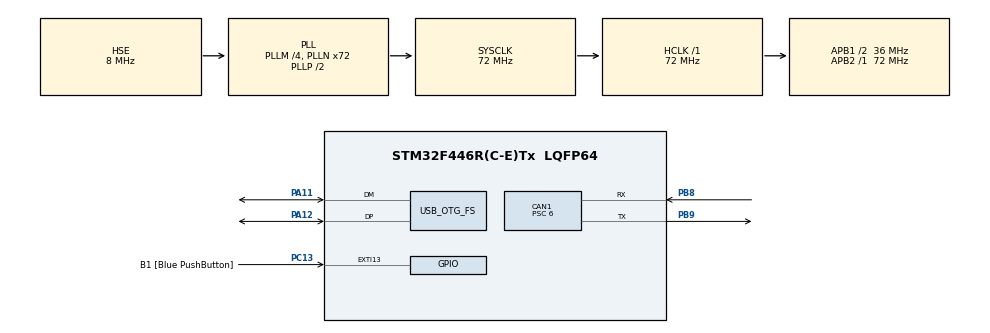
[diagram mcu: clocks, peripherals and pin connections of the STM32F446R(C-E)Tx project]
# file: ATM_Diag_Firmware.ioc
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CAN1.BS1=CAN_BS1_12TQ
CAN1.BS2=CAN_BS2_1TQ
CAN1.CalculateBaudRate=428571
CAN1.CalculateTimeBit=2333
CAN1.CalculateTimeQuantum=166.66666666666669
CAN1.NART=ENABLE
CAN1.Prescaler=6
FREERTOS.Tasks01=defaultTask,24,128,StartDefaultTask,Default,NULL,Dynamic,NULL,NULL
FREERTOS.configENABLE_FPU=1
FREERTOS.configUSE_NEWLIB_REENTRANT=1
Mcu.Family=STM32F4
Mcu.Name=STM32F446R(C-E)Tx
Mcu.Package=LQFP64
NVIC.CAN1_RX0_IRQn=true\:6\:0\:true\:false\:true\:true\:true\:true\:true
NVIC.CAN1_TX_IRQn=true\:7\:0\:true\:false\:true\:true\:true\:true\:true
NVIC.OTG_FS_IRQn=true\:5\:0\:true\:false\:true\:true\:true\:true\:true
NVIC.PriorityGroup=NVIC_PRIORITYGROUP_4
NVIC.TIM2_IRQn=true\:15\:0\:false\:false\:true\:false\:false\:true\:true
NVIC.TimeBase=TIM2_IRQn
NVIC.TimeBaseIP=TIM2
PA11.Mode=Device_Only
PA11.Signal=USB_OTG_FS_DM
PA12.Mode=Device_Only
PA12.Signal=USB_OTG_FS_DP
PA13.GPIO_Label=TMS
PA13.Mode=Serial_Wire
PA13.Signal=SYS_JTMS-SWDIO
PA14.GPIO_Label=TCK
PA14.Mode=Serial_Wire
PA14.Signal=SYS_JTCK-SWCLK
PB8.Mode=CAN_Activate
PB8.Signal=CAN1_RX
PB9.Mode=CAN_Activate
PB9.Signal=CAN1_TX
PC13.GPIO_Label=B1 [Blue PushButton]
PC13.GPIO_ModeDefaultEXTI=GPIO_MODE_IT_FALLING
PC13.Signal=GPXTI13
PC14-OSC32_IN.Mode=LSE-External-Oscillator
PC14-OSC32_IN.Signal=RCC_OSC32_IN
PC15-OSC32_OUT.Mode=LSE-External-Oscillator
PC15-OSC32_OUT.Signal=RCC_OSC32_OUT
PH0-OSC_IN.Mode=HSE-External-Oscillator
PH0-OSC_IN.Signal=RCC_OSC_IN
PH1-OSC_OUT.Mode=HSE-External-Oscillator
PH1-OSC_OUT.Signal=RCC_OSC_OUT
ProjectManager.HeapSize=0x200
ProjectManager.StackSize=0x400
ProjectManager.TargetToolchain=STM32CubeIDE
RCC.48MHZClocksFreq_Value=84000000
RCC.AHBFreq_Value=72000000
RCC.APB1CLKDivider=RCC_HCLK_DIV2
RCC.APB1Freq_Value=36000000
RCC.APB1TimFreq_Value=72000000
RCC.APB2Freq_Value=72000000
RCC.APB2TimFreq_Value=72000000
RCC.CortexFreq_Value=72000000
RCC.FLatency-AdvancedSettings=FLASH_LATENCY_2
RCC.HCLKFreq_Value=72000000
RCC.HSE_VALUE=8000000
RCC.HSI_VALUE=16000000
RCC.PLLM=4
RCC.PLLN=72
RCC.PLLQ=3
RCC.PLLSAIM=8
RCC.PLLSAIN=96
RCC.PLLSourceVirtual=RCC_PLLSOURCE_HSE
RCC.SYSCLKFreq_VALUE=72000000
RCC.SYSCLKSource=RCC_SYSCLKSOURCE_PLLCLK
RCC.USBFreq_Value=48000000
RCC.VCOOutputFreq_Value=144000000
USB_DEVICE.CLASS_NAME_FS=CDC
USB_DEVICE.VirtualMode-CDC_FS=Cdc
USB_DEVICE.VirtualModeFS=Cdc_FS
USB_OTG_FS.VirtualMode=Device_Only
VP_FREERTOS_VS_CMSIS_V2.Mode=CMSIS_V2
VP_SYS_VS_tim2.Mode=TIM2
VP_USB_DEVICE_VS_USB_DEVICE_CDC_FS.Mode=CDC_FS
board=NUCLEO-F446RE

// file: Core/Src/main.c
/* USER CODE BEGIN Header */
/**
  ******************************************************************************
  * @file           : main.c
  * @brief          : Main program body
  ******************************************************************************
  * @attention
  *
  * Copyright (c) 2025 STMicroelectronics.
  * All rights reserved.
  *
  * This software is licensed under terms that can be found in the LICENSE file
  * in the root directory of this software component.
  * If no LICENSE file comes with this software, it is provided AS-IS.
  *
  ******************************************************************************
  */
/* USER CODE END Header */
#include "main.h"
#include "cmsis_os.h"
#include "can.h"
#include "usb_device.h"
#include "gpio.h"

void SystemClock_Config(void);
void MX_FREERTOS_Init(void);

int main(void)
{

  /* MCU Configuration--------------------------------------------------------*/

  /* Reset of all peripherals, Initializes the Flash interface and the Systick. */
  HAL_Init();

  /* Configure the system clock */
  SystemClock_Config();

  /* USER CODE BEGIN SysInit */
  SystemCoreClockUpdate();

  /* USER CODE END SysInit */

  /* Initialize all configured peripherals */
  MX_GPIO_Init();
  MX_CAN1_Init();

  /* Init scheduler */
  osKernelInitialize();

  /* Call init function for freertos objects (in cmsis_os2.c) */
  MX_FREERTOS_Init();

  /* Start scheduler */
  osKernelStart();

  /* We should never get here as control is now taken by the scheduler */

  /* Infinite loop */
  while (1)
  {

  }
}

void SystemClock_Config(void)
{
  RCC_OscInitTypeDef RCC_OscInitStruct = {0};
  RCC_ClkInitTypeDef RCC_ClkInitStruct = {0};

  /** Configure the main internal regulator output voltage
  */
  __HAL_RCC_PWR_CLK_ENABLE();
  __HAL_PWR_VOLTAGESCALING_CONFIG(PWR_REGULATOR_VOLTAGE_SCALE3);

  /** Initializes the RCC Oscillators according to the specified parameters
  * in the RCC_OscInitTypeDef structure.
  */
  RCC_OscInitStruct.OscillatorType = RCC_OSCILLATORTYPE_HSE;
  RCC_OscInitStruct.HSEState = RCC_HSE_ON;
  RCC_OscInitStruct.PLL.PLLState = RCC_PLL_ON;
  RCC_OscInitStruct.PLL.PLLSource = RCC_PLLSOURCE_HSE;
  RCC_OscInitStruct.PLL.PLLM = 4;
  RCC_OscInitStruct.PLL.PLLN = 72;
  RCC_OscInitStruct.PLL.PLLP = RCC_PLLP_DIV2;
  RCC_OscInitStruct.PLL.PLLQ = 3;
  RCC_OscInitStruct.PLL.PLLR = 2;
  if (HAL_RCC_OscConfig(&RCC_OscInitStruct) != HAL_OK)
  {
    Error_Handler();
  }

  /** Initializes the CPU, AHB and APB buses clocks
  */
  RCC_ClkInitStruct.ClockType = RCC_CLOCKTYPE_HCLK|RCC_CLOCKTYPE_SYSCLK
                              |RCC_CLOCKTYPE_PCLK1|RCC_CLOCKTYPE_PCLK2;
  RCC_ClkInitStruct.SYSCLKSource = RCC_SYSCLKSOURCE_PLLCLK;
  RCC_ClkInitStruct.AHBCLKDivider = RCC_SYSCLK_DIV1;
  RCC_ClkInitStruct.APB1CLKDivider = RCC_HCLK_DIV2;
  RCC_ClkInitStruct.APB2CLKDivider = RCC_HCLK_DIV1;

  if (HAL_RCC_ClockConfig(&RCC_ClkInitStruct, FLASH_LATENCY_2) != HAL_OK)
  {
    Error_Handler();
  }
}

void HAL_TIM_PeriodElapsedCallback(TIM_HandleTypeDef *htim)
{
  if (htim->Instance == TIM2) {
    HAL_IncTick();
  }
}

void Error_Handler(void)
{
  __disable_irq();
  while (1)
  {
  }
}

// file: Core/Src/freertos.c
/* USER CODE BEGIN Header */
/**
  ******************************************************************************
  * File Name          : freertos.c
  * Description        : Code for freertos applications
  ******************************************************************************
  * @attention
  *
  * Copyright (c) 2025 STMicroelectronics.
  * All rights reserved.
  *
  * This software is licensed under terms that can be found in the LICENSE file
  * in the root directory of this software component.
  * If no LICENSE file comes with this software, it is provided AS-IS.
  *
  ******************************************************************************
  */
/* USER CODE END Header */

#include "FreeRTOS.h"
#include "task.h"
#include "main.h"
#include "cmsis_os.h"

/* Definitions for defaultTask */
osThreadId_t defaultTaskHandle;
const osThreadAttr_t defaultTask_attributes = {
  .name = "defaultTask",
  .stack_size = 128 * 4,
  .priority = (osPriority_t) osPriorityNormal,
};

/* USER CODE BEGIN FunctionPrototypes */
void Task_Prepare_Request(void* arg);
/* USER CODE END FunctionPrototypes */

void StartDefaultTask(void *argument);

extern void MX_USB_DEVICE_Init(void);
void MX_FREERTOS_Init(void); /* (MISRA C 2004 rule 8.1) */

void MX_FREERTOS_Init(void) {

  /* Create the thread(s) */
  /* creation of defaultTask */
  defaultTaskHandle = osThreadNew(StartDefaultTask, NULL, &defaultTask_attributes);

  /* USER CODE BEGIN RTOS_THREADS */
  /* add threads, ... */

  // xTaskCreate(Task_Prepare_Request,  "PrepareRequest",  64, NULL, osPriorityHigh7, NULL);
  // xTaskCreate(Task_Process_Request,  "ProcessRequest",  64, NULL, osPriorityHigh6, NULL);
  // xTaskCreate(Task_Process_Response, "ProcessResponse", 64, NULL, osPriorityHigh5, NULL);

  /* USER CODE END RTOS_THREADS */

}

void StartDefaultTask(void *argument)
{
  /* init code for USB_DEVICE */
  MX_USB_DEVICE_Init();
  /* USER CODE BEGIN StartDefaultTask */
  /* Infinite loop */
  for(;;)
  {
    osDelay(100);
  }
  /* USER CODE END StartDefaultTask */
}

/* USER CODE BEGIN Application */

void Task_Prepare_Request(void* arg){
	// wait notify from USB ISR
	// receive USB data and prepare CAN msg with data from USB
	// add CAN msg to Tx CAN Buffer
}

void Task_Process_Request(void* arg){
	// wait notify from Task_Prepare_Request
	// CanIf_Transmit
}

void Task_Process_Response(void* arg){
	// wait notify from CAN ISR
	// get CAN msg
	// prepare data from CAN msg
	// send USB data
}

/* USER CODE END Application */
